# T113-S3 register map
Vendor: Allwinner; Series: T113-S3; File version: 0.1
CPU: other 0, little endian, MPU, no FPU, 0 interrupt priority bits
Registers are 32-bit, read-write, reset 0x0 unless marked. A register's access mark holds for its fields unless they carry their own. Offsets are from the block's base; [hi:lo] are bit positions.

## SYS_CFG
Base 0x03000000
0x08 DSP_BOOT_RAMMAP_REG reset 0x1 — DSP Boot SRAM Remap Control Register
  [0] DSP — BOOT SRAM REMAP ENABLE 0: DSP 128K Local SRAM Remap for DSP_SYS 1: DSP 128K Local SRAM Remap for System Boot After system boots up, this bit must be set to 0 before using DSP.
    0=128K_Local_SRAM_Remap_for_DSP_SYS (DSP 128K Local SRAM Remap for DSP_SYS); 1=128K_Local_SRAM_Remap_for_System (DSP 128K Local SRAM Remap for System Boot After system boots up, this bit must be set to 0 before using DSP.)
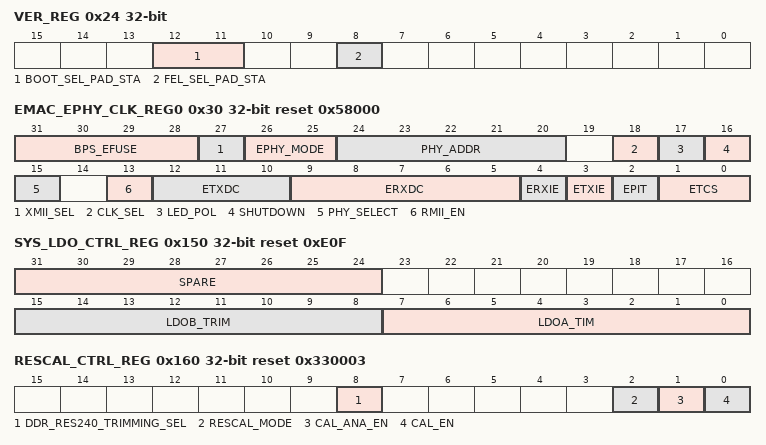
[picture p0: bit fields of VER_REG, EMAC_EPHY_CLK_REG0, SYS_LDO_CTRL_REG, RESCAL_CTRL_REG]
0x24 VER_REG reset not defined — Version Register
  [12:11] BOOT_SEL_PAD_STA ro — The value of this bit decides the priority order for each medium type to be selected as the boot media.
  [8] FEL_SEL_PAD_STA ro — Fel_Select_Pin_Status 0: Run_FEL 1: Try Media Boot
    0=Run_FEL; 1=Try (Try Media Boot)
0x30 EMAC_EPHY_CLK_REG0 reset 0x58000 — EMAC-EPHY Clock Register 0
  [31:28] BPS_EFUSE
  [27] XMII_SEL — 0: Internal SMI and MII 1: External SMI and MII
    0=Internal SMI and MII; 1=External SMI and MII
  [26:25] EPHY_MODE — Operation Mode Selection 00: Normal Mode 01: Simulation Mode 10: AFE Test Mode 11: Reserved
    0=Normal Mode; 1=Simulation Mode; 2=AFE (AFE Test Mode)
  [24:20] PHY_ADDR — PHY Address
  [18] CLK_SEL — 0: 25 MHz 1: 24 MHz
    0=25 MHz; 1=24 MHz
  [17] LED_POL — 0: High active 1: Low active
    0=High active; 1=Low (Low active)
  [16] SHUTDOWN — 0: Power up 1: Shut down
    0=Power up; 1=Shut down
  [15] PHY_SELECT — 0: External PHY 1: Internal PHY
    0=External PHY; 1=Internal PHY
  [13] RMII_EN — 0: Disable RMII Module 1: Enable RMII Module This bit is prior to bit[2]. When this bit is asserted, the MII and RGMII interfaces will be both disabled.
    0=Disable RMII Module; 1=Enable RMII Module This bit is prior to bit[2]. When this bit is asserted, the MII and RGMII interfaces will be both disabled.
  [12:10] ETXDC — Configure EMAC Transmit Clock Delay Chain
  [9:5] ERXDC — Configure EMAC Receive Clock Delay Chain
  [4] ERXIE — Enable EMAC Receive Clock Invertor 0: Disabled 1: Enabled
    0=Disabled; 1=Enabled
  [3] ETXIE — Enable EMAC Transmit Clock Invertor 0: Disabled 1: Enabled
    0=Disabled; 1=Enabled
  [2] EPIT — EMAC PHY Interface Type 0: MII 1: RGMII
    0=MII; 1=RGMII
  [1:0] ETCS — EMAC Transmit Clock Source 00: Transmit clock source for MII 01: External transmit clock source for GMII and RGMII 10: Internal transmit clock source for GMII and RGMII 11: Reserved
    0=Transmit clock source for MII; 1=External transmit clock source for GMII and RGMII; 2=Internal transmit clock source for GMII and RGMII
0x150 SYS_LDO_CTRL_REG reset 0xE0F — System LDO Control Register
  [31:24] SPARE — Reserved spare register
  [15:8] LDOB_TRIM — LDOB Trimming. Adjust LDOB output, only the low 6-bit is used. 000000:1.167 000001:1.18 000010:1.193 000011:1.207 000100:1.22 000101:1.233 000110:1.247 000111:1.260 001000:1.273 001001:1.287 001010:1.3 001011:1.313 001100:1.327 001101:1.340 001110:1.353 (default) 001111:1.367 010000:1.38 010001:1.393 010010:1.407 010011:1.42 010100:1.433 010101:1.447 010110:1.46 010111:1.473 011000:1.487 011001:1.5 011010:1.513 011011:1.527 011100:1.54 011101:1.553 011110:1.567 011111:1.58 100000:1.593 100001:1.607 100010:1.627 100011:1.64 100100:1.653 100101:1.667 100110:1.680 100111:1.693 101000:1.707 101001:1.720 101010:1.733 101011:1.747 101100:1.76 101101:1.773 101110:1.787 101111:1.8 110000:1.813 110001:1.827 110010:1.84 110011:1.853 110100:1.867 110101:1.88 110110:1.893 110111:1.907 111000:1.92 111001:1.933 111010:1.947 111011:1.96 111100:1.973 111101:1.987 111110:2 111111:2.013
  [7:0] LDOA_TIM — LDOA Trimming Adjust LDOA output, only the low 5-bit is used. 00000:1.593 00001:1.607 00010:1.627 00011:1.64 00100:1.653 00101:1.667 00110:1.680 00111:1.693 01000:1.707 01001:1.720 01010:1.733 01011:1.747 01100:1.76 01101:1.773 01110:1.787 01111:1.8 (default) 10000:1.813 10001:1.827 10010:1.84 10011:1.853 10100:1.867 10101:1.88 10110:1.893 10111:1.907 11000:1.92 11001:1.933 11010:1.947 11011:1.96 11100:1.973 11101:1.987 11110:2 11111:2.013
0x160 RESCAL_CTRL_REG reset 0x330003 — Resistor Calibration Control Register
  [8] DDR_RES240_TRIMMING_SEL — 240ohms Resistor Trimming Source Select 0: Trimming value from RESCAL 1: Trimming value from RES240_TRIM
    0=Trimming_value_from_RESCAL; 1=Trimming_value_from_RES240_TRIM
  [2] RESCAL_MODE — RESCAL Calibration Mode Select 0: Auto Calibration 1: Reserved
    0=Auto Calibration
  [1] CAL_ANA_EN — Calibration Circuits Analog Enable 0: Disable 1: Enable
    0=Disable; 1=Enable
  [0] CAL_EN — Auto Calibration Enable 0: Disable 1: Enable
    0=Disable; 1=Enable
0x168 RES240_CTRL_REG reset 0x33 — 240ohms Resistor Manual Control Register
  [5:0] DDR_RES240_TRIM — 240ohms Resistor trimming bit
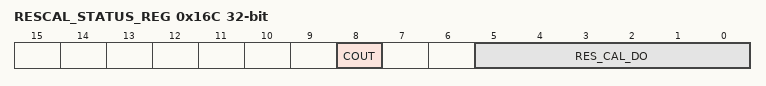
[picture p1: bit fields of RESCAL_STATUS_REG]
0x16C RESCAL_STATUS_REG — Resistor Calibration Status Register
  [8] COUT ro — Calibration Circuits Analog Compare Output
  [5:0] RES_CAL_DO ro — RESCAL Calibration Results Output
